# MKW40Z4 register map
Vendor: Freescale Semiconductor, Inc.; Series: Kinetis_W; File version: 1.6
CPU: CM0PLUS r0p0, little endian, no MPU, no FPU, VTOR, 2 interrupt priority bits
Registers are 32-bit, read-write, reset 0x0 unless marked. A register's access mark holds for its fields unless they carry their own. Offsets are from the block's base; [hi:lo] are bit positions; {n}, {i} and the like mark numbered series; 'fields as' and 'values as' point back to an identical list.

## PORTB — Pin Control and Interrupts
Base 0x4004A000; register names take the prefix PORTB_
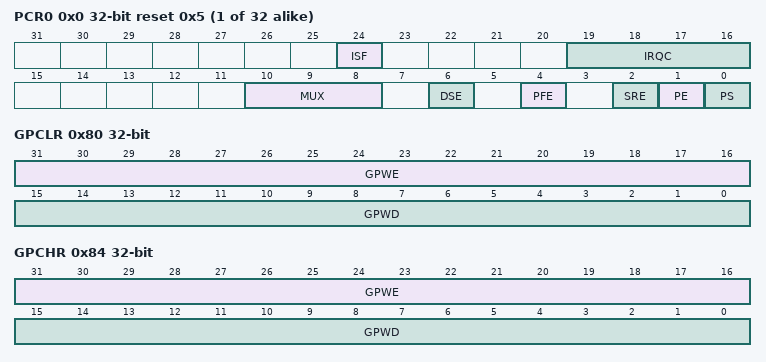
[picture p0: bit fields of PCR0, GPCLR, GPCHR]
{0x0+4i} PCR{i} (i=0..31) reset 0x5 — Pin Control Register n
  [24] ISF — Interrupt Status Flag
    0=Configured interrupt is not detected; 1=Configured interrupt is detected. If the pin is configured to generate a DMA request, then the corresponding flag will be cleared automatically at the completion of the requested DMA transfer. Otherwise, the flag remains set until a logic 1 is written to the flag. If the pin is configured for a level sensitive interrupt and the pin remains asserted, then the flag is set again immediately after it is cleared.
  [19:16] IRQC — Interrupt Configuration
    0=Interrupt/DMA request disabled; 1=DMA request on rising edge; 2=DMA request on falling edge; 3=DMA request on either edge; 8=Interrupt when logic 0; 9=Interrupt on rising-edge; 10=Interrupt on falling-edge; 11=Interrupt on either edge; 12=Interrupt when logic 1
  [10:8] MUX — Pin Mux Control
    0=Pin disabled (analog); 1=Alternative 1 (GPIO); {v}=Alternative {v} (chip-specific) (v=2..7)
  [6] DSE — Drive Strength Enable
    0=Low drive strength is configured on the corresponding pin, if pin is configured as a digital output; 1=High drive strength is configured on the corresponding pin, if pin is configured as a digital output
  [4] PFE — Passive Filter Enable
    0=Passive input filter is disabled on the corresponding pin; 1=Passive input filter is enabled on the corresponding pin, if the pin is configured as a digital input. Refer to the device data sheet for filter characteristics.
  [2] SRE — Slew Rate Enable
    0=Fast slew rate is configured on the corresponding pin, if the pin is configured as a digital output; 1=Slow slew rate is configured on the corresponding pin, if the pin is configured as a digital output
  [1] PE — Pull Enable
    0=Internal pullup or pulldown resistor is not enabled on the corresponding pin; 1=Internal pullup or pulldown resistor is enabled on the corresponding pin, if the pin is configured as a digital input
  [0] PS — Pull Select
    0=Internal pulldown resistor is enabled on the corresponding pin, if the corresponding PE field is set; 1=Internal pullup resistor is enabled on the corresponding pin, if the corresponding PE field is set
0x80 GPCLR wo — Global Pin Control Low Register
  [31:16] GPWE — Global Pin Write Enable
    0=Corresponding Pin Control Register is not updated with the value in GPWD; 1=Corresponding Pin Control Register is updated with the value in GPWD
  [15:0] GPWD — Global Pin Write Data
0x84 GPCHR wo — Global Pin Control High Register
  fields as GPCLR
0xA0 ISFR — Interrupt Status Flag Register
  [31:0] ISF — Interrupt Status Flag
    values as PCR0.ISF

## PORTC — Pin Control and Interrupts
Base 0x4004B000; register names take the prefix PORTC_
Registers as PORTB.

## LTC
Base 0x40058000
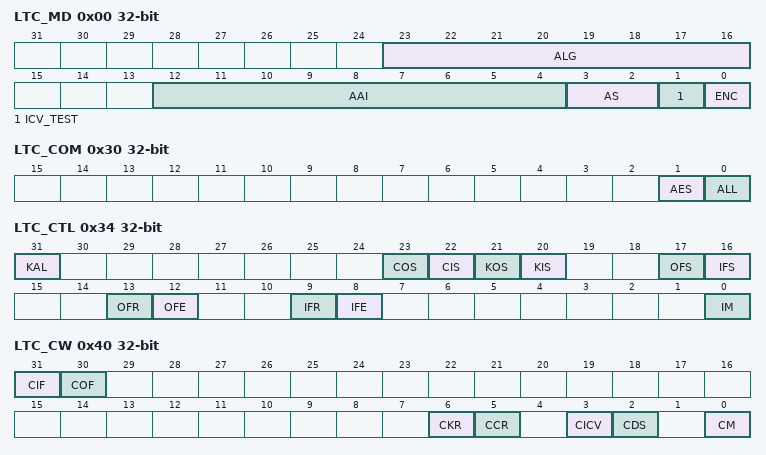
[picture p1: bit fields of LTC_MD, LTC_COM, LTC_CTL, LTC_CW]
0x00 LTC_MD — LTC Mode Register (non-PKHA/non-RNG use)
  [23:16] ALG
    16=AES
  [12:4] AAI
  [3:2] AS
    0=Update; 1=Initialize; 2=Finalize; 3=Initialize/Finalize
  [1] ICV_TEST
  [0] ENC
    0=Decrypt; 1=Encrypt
0x08 LTC_KS ro reset 0x10 — LTC Key Size Register
0x10 LTC_DS — LTC Data Size Register
  [11:0] DS
0x18 LTC_ICVS — LTC ICV Size Register
  [4:0] ICVS
0x30 LTC_COM — LTC Command Register
  [1] AES wo
    0=Do Not Reset; 1=Reset AES Accelerator
  [0] ALL wo
    0=Do Not Reset; 1=Reset all CHAs in use by this CCB
0x34 LTC_CTL — LTC Control Register
  [31] KAL
    0=Key Register is readable; 1=Key Register is not readable
  [23] COS
    0=Do Not Byte Swap Data; 1=Byte Swap Data
  [22] CIS
    0=Do Not Byte Swap Data; 1=Byte Swap Data
  [21] KOS
    0=Do Not Byte Swap Data; 1=Byte Swap Data
  [20] KIS
    0=Do Not Byte Swap Data; 1=Byte Swap Data
  [17] OFS
    0=Do Not Byte Swap Data; 1=Byte Swap Data
  [16] IFS
    0=Do Not Byte Swap Data; 1=Byte Swap Data
  [13] OFR
    0=DMA request size is 1 entry; 1=DMA request size is 4 entries
  [12] OFE
    0=DMA Request and Done signals disabled for the Output FIFO; 1=DMA Request and Done signals enabled for the Output FIFO
  [9] IFR
    values as OFR
  [8] IFE
    0=DMA Request and Done signals disabled for the Input FIFO; 1=DMA Request and Done signals enabled for the Input FIFO
  [0] IM
    0=Interrupt not masked; 1=Interrupt masked
0x40 LTC_CW — LTC Clear Written Register
  [31] CIF wo, [30] COF wo, [6] CKR wo, [5] CCR wo, [3] CICV wo, [2] CDS wo, [0] CM wo
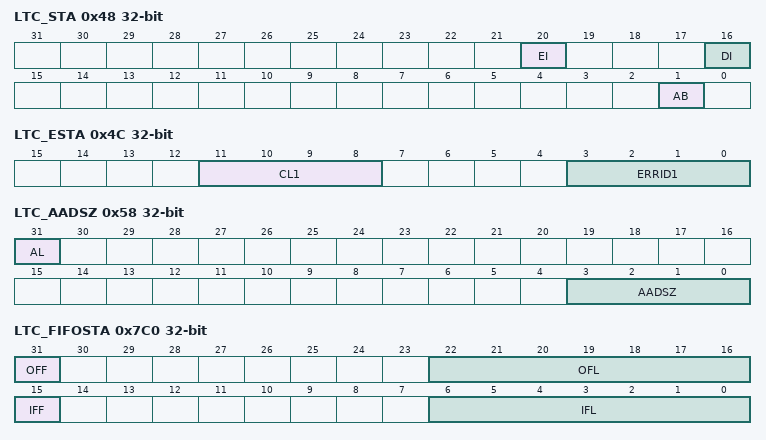
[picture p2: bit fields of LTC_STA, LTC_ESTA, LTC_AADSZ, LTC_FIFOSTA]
0x48 LTC_STA — LTC Status Register
  [20] EI ro
    0=Not Error; 1=Error Interrupt
  [16] DI
  [1] AB ro
    0=AESA Idle; 1=AESA Busy
0x4C LTC_ESTA ro — LTC Error Status Register
  [11:8] CL1
    0=LTC General Error; 1=AES
  [3:0] ERRID1
    1=Mode Error; 2=Data Size Error; 3=Key Size Error; 6=Data Arrived out of Sequence Error; 10=ICV Check Failed; 11=Internal Hardware Failure; 12=CCM AAD Size Error (either 1. AAD flag in B0 =1 and no AAD type provided, 2. AAD flag in B0 = 0 and AAD povided, or 3. AAD flag in B0 =1 and not enough AAD provided - expecting more based on AAD size.); 15=Invalid Crypto Engine Selected
0x58 LTC_AADSZ — LTC AAD Size Register
  [31] AL, [3:0] AADSZ
{0x100+4i} LTC_CTXR_{i} (i=0..15) — LTC Context Register
  [31:0] CTX
{0x200+4i} LTC_KEYR_{i} (i=0..7) — LTC Key Registers
  [31:0] KEY
0x7C0 LTC_FIFOSTA ro — LTC FIFO Status Register
  [31] OFF, [22:16] OFL, [15] IFF, [6:0] IFL
0x7E0 LTC_IFIFO wo — LTC Input Data FIFO
0x7F0 LTC_OFIFO ro — LTC Output Data FIFO
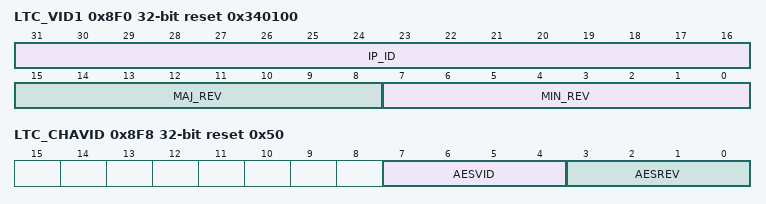
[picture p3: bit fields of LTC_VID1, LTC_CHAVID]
0x8F0 LTC_VID1 ro reset 0x340100 — LTC Version ID Register
  [31:16] IP_ID, [15:8] MAJ_REV, [7:0] MIN_REV
0x8F8 LTC_CHAVID ro reset 0x50 — LTC CHA Version ID Register
  [7:4] AESVID, [3:0] AESREV
